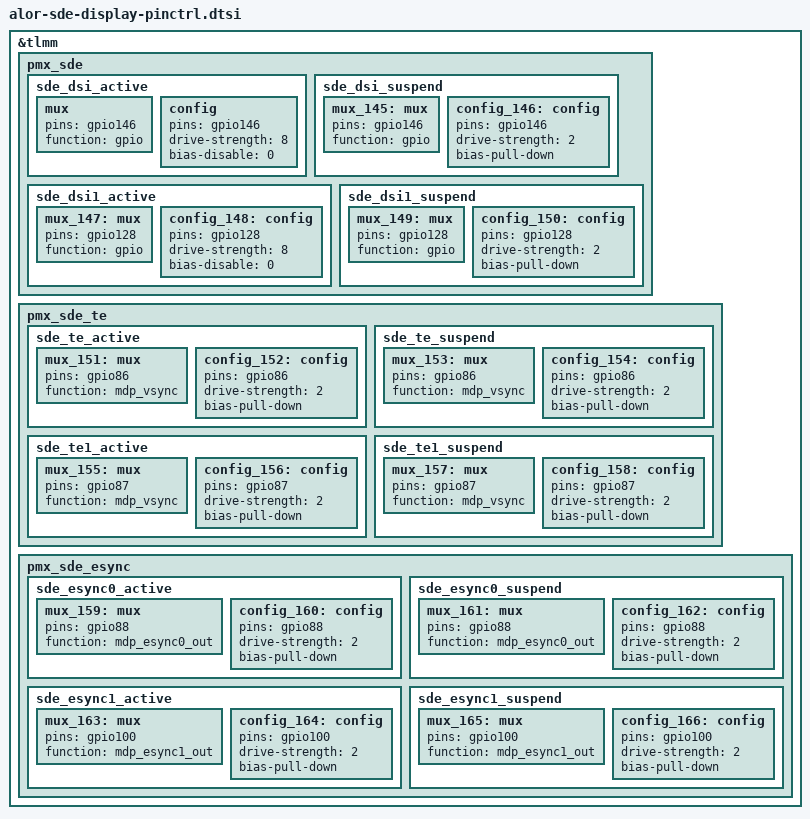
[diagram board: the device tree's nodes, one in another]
// SPDX-License-Identifier: BSD-3-Clause
/*
 * Copyright (c) Qualcomm Technologies, Inc. and/or its subsidiaries.
 */

&tlmm {
	pmx_sde: pmx_sde {
		sde_dsi_active: sde_dsi_active {
			mux: mux {
				pins = "gpio146";
				function = "gpio";
			};

			config: config {
				pins = "gpio146";
				drive-strength = <8>;   /* 8 mA */
				bias-disable = <0>;   /* no pull */
			};
		};

		sde_dsi_suspend: sde_dsi_suspend {
			mux_145: mux {
				pins = "gpio146";
				function = "gpio";
			};

			config_146: config {
				pins = "gpio146";
				drive-strength = <2>;   /* 2 mA */
				bias-pull-down;         /* PULL DOWN */
			};
		};

		sde_dsi1_active: sde_dsi1_active {
			mux_147: mux {
				pins = "gpio128";
				function = "gpio";
			};

			config_148: config {
				pins = "gpio128";
				drive-strength = <8>;   /* 8 mA */
				bias-disable = <0>;   /* no pull */
			};
		};

		sde_dsi1_suspend: sde_dsi1_suspend {
			mux_149: mux {
				pins = "gpio128";
				function = "gpio";
			};

			config_150: config {
				pins = "gpio128";
				drive-strength = <2>;   /* 2 mA */
				bias-pull-down;         /* PULL DOWN */
			};
		};
	};

	pmx_sde_te: pmx_sde_te {
		sde_te_active: sde_te_active {
			mux_151: mux {
				pins = "gpio86";
				function = "mdp_vsync";
			};

			config_152: config {
				pins = "gpio86";
				drive-strength = <2>;   /* 2 mA */
				bias-pull-down;         /* PULL DOWN */
			};
		};

		sde_te_suspend: sde_te_suspend {
			mux_153: mux {
				pins = "gpio86";
				function = "mdp_vsync";
			};

			config_154: config {
				pins = "gpio86";
				drive-strength = <2>;   /* 2 mA */
				bias-pull-down;         /* PULL DOWN */
			};
		};

		sde_te1_active: sde_te1_active {
			mux_155: mux {
				pins = "gpio87";
				function = "mdp_vsync";
			};

			config_156: config {
				pins = "gpio87";
				drive-strength = <2>;   /* 2 mA */
				bias-pull-down;         /* PULL DOWN */
			};
		};

		sde_te1_suspend: sde_te1_suspend {
			mux_157: mux {
				pins = "gpio87";
				function = "mdp_vsync";
			};

			config_158: config {
				pins = "gpio87";
				drive-strength = <2>;   /* 2 mA */
				bias-pull-down;         /* PULL DOWN */
			};
		};
	};

	pmx_sde_esync: pmx_sde_esync {
		sde_esync0_active: sde_esync0_active {
			mux_159: mux {
				pins = "gpio88";
				function = "mdp_esync0_out";
			};

			config_160: config {
				pins = "gpio88";
				drive-strength = <2>;   /* 2 mA */
				bias-pull-down;         /* PULL DOWN */
			};
		};

		sde_esync0_suspend: sde_esync0_suspend {
			mux_161: mux {
				pins = "gpio88";
				function = "mdp_esync0_out";
			};

			config_162: config {
				pins = "gpio88";
				drive-strength = <2>;   /* 2 mA */
				bias-pull-down;         /* PULL DOWN */
			};
		};

		sde_esync1_active: sde_esync1_active {
			mux_163: mux {
				pins = "gpio100";
				function = "mdp_esync1_out";
			};

			config_164: config {
				pins = "gpio100";
				drive-strength = <2>;   /* 2 mA */
				bias-pull-down;         /* PULL DOWN */
			};
		};

		sde_esync1_suspend: sde_esync1_suspend {
			mux_165: mux {
				pins = "gpio100";
				function = "mdp_esync1_out";
			};

			config_166: config {
				pins = "gpio100";
				drive-strength = <2>;   /* 2 mA */
				bias-pull-down;         /* PULL DOWN */
			};
		};
	};
};
